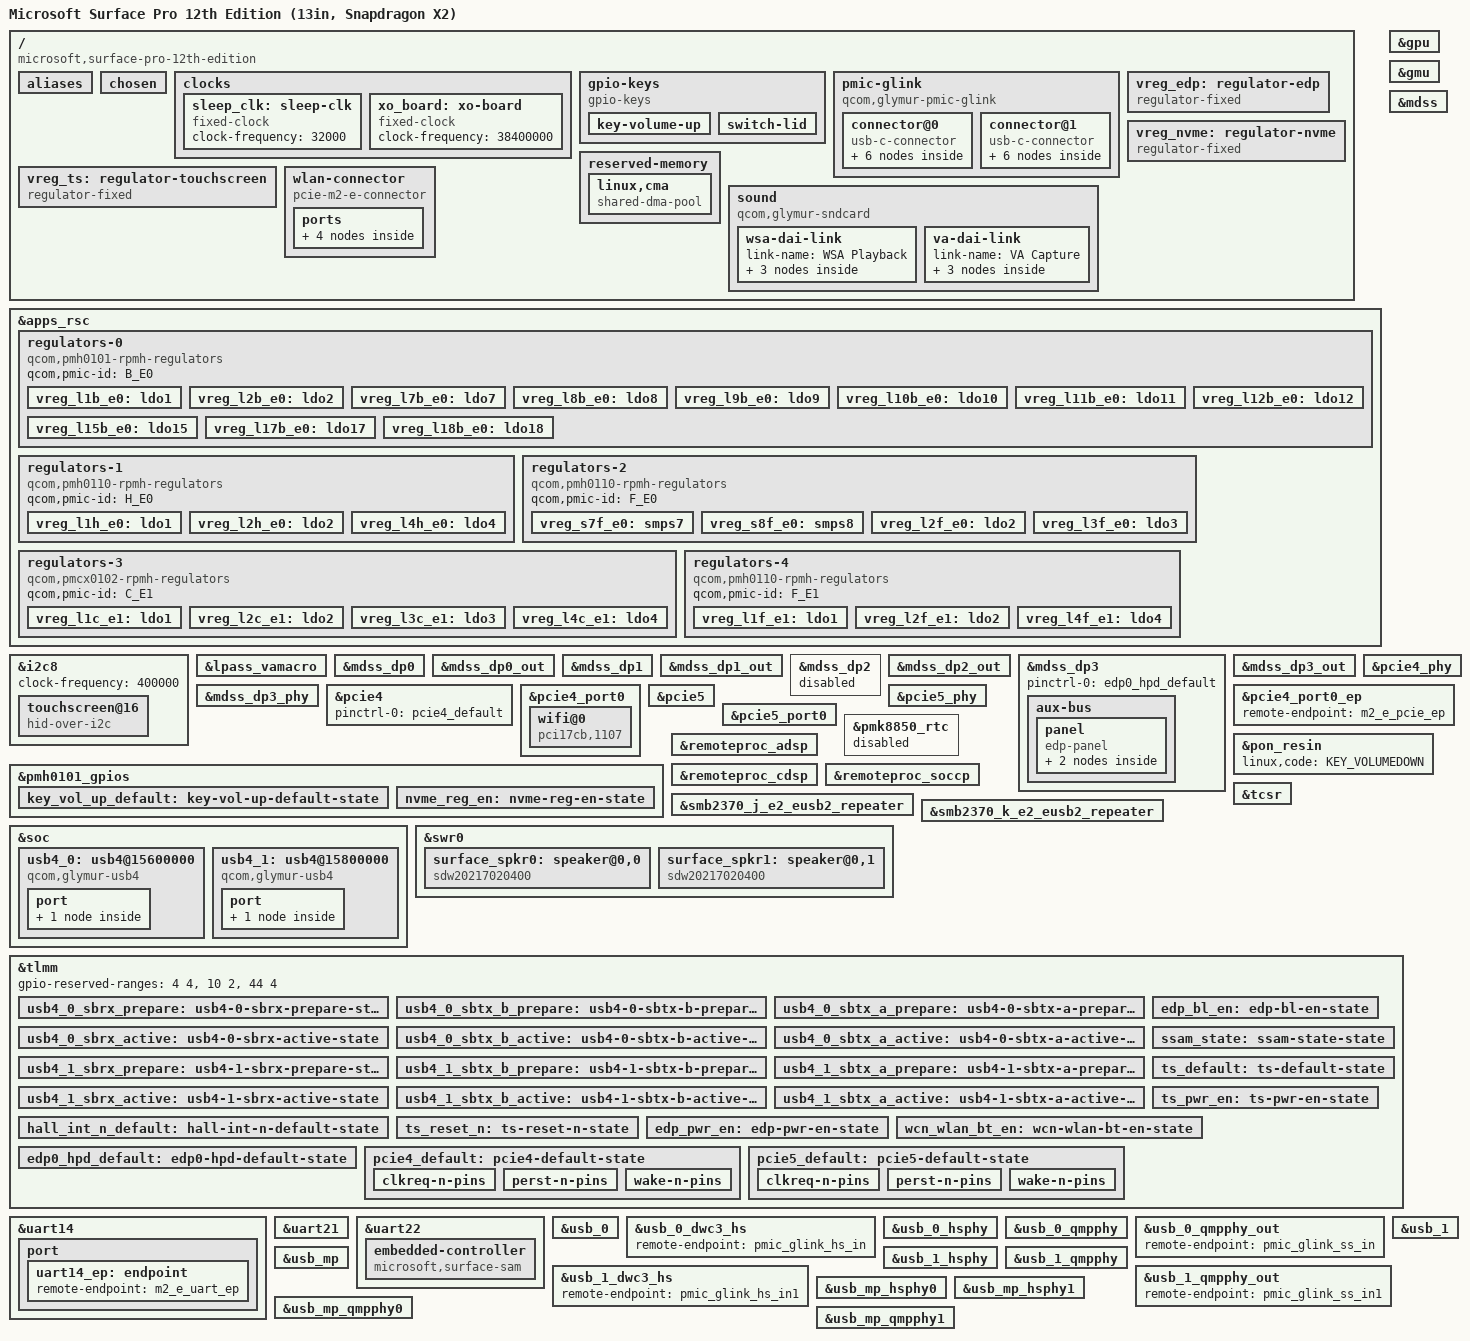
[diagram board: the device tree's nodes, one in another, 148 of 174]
// SPDX-License-Identifier: BSD-3-Clause
/*
 * Microsoft Surface Pro 12th Edition, the 13-inch tablet with the
 * Snapdragon X2 Plus X2P-64-100 or X2 Elite X2E-78-100 (Mahua).
 *
 * Bus and pin assignments follow the ACPI tables in Microsoft's firmware
 * package for the tablet. They match the Surface Laptop 8 13.8-inch apart
 * from the touchscreen, the missing touchpad and the buttons, so the SoC
 * wiring is that laptop's.
 *
 * Copyright (c) Qualcomm Technologies, Inc. and/or its subsidiaries.
 * Copyright (c) 2026, Birk Skyum <birk.skyum@pm.me>
 */
/dts-v1/;

#include "mahua.dtsi"

#include "pmcx0102.dtsi"
#include "pmh0101.dtsi"
#include "pmh0110-glymur.dtsi"
#include "pmk8850.dtsi"
#include "smb2370.dtsi"

#include <dt-bindings/input/gpio-keys.h>
#include <dt-bindings/input/input.h>

/* As mahua-crd.dts: one pmcx0102 die on SPMI0. */
/delete-node/ &pmcx0102_d_e0;
/delete-node/ &pmcx0102_d0_thermal;

/ {
	compatible = "microsoft,surface-pro-12th-edition", "qcom,mahua";
	model = "Microsoft Surface Pro 12th Edition (13in, Snapdragon X2)";

	aliases {
		i2c8 = &i2c8;

		serial0 = &uart21;
		serial1 = &uart14;
	};

	chosen {
	};

	clocks {
		sleep_clk: sleep-clk {
			compatible = "fixed-clock";
			clock-frequency = <32000>;
			#clock-cells = <0>;
		};

		xo_board: xo-board {
			compatible = "fixed-clock";
			clock-frequency = <38400000>;
			#clock-cells = <0>;
		};
	};

	/*
	 * ACPI \_SB.LIGE takes its wake interrupt from GPIO controller pin
	 * 0x440, which is TLMM 2, and \_SB.LID0 reads TLMM 2 directly. On the
	 * tablet the Hall sensor reports the folded keyboard cover.
	 *
	 * MSHW0040 lists two PMIC lines for the volume buttons, up first
	 * (0x72) and down second (0x208), the numbers and order Qualcomm's
	 * reference tables give their volume up and down keys. The Glymur
	 * CRD wires those to PMH0101 GPIO 6 and RESIN.
	 */
	gpio-keys {
		compatible = "gpio-keys";

		pinctrl-0 = <&hall_int_n_default>, <&key_vol_up_default>;
		pinctrl-names = "default";

		key-volume-up {
			label = "Volume Up";
			linux,code = <KEY_VOLUMEUP>;
			gpios = <&pmh0101_gpios 6 GPIO_ACTIVE_LOW>;
			debounce-interval = <15>;
			linux,can-disable;
			wakeup-source;
		};

		switch-lid {
			label = "lid";
			gpios = <&tlmm 2 GPIO_ACTIVE_LOW>;
			linux,input-type = <EV_SW>;
			linux,code = <SW_LID>;
			wakeup-source;
		};
	};

	pmic-glink {
		compatible = "qcom,glymur-pmic-glink",
			     "qcom,pmic-glink";
		#address-cells = <1>;
		#size-cells = <0>;

		connector@0 {
			compatible = "usb-c-connector";
			reg = <0>;
			power-role = "dual";
			data-role = "dual";

			ports {
				#address-cells = <1>;
				#size-cells = <0>;

				port@0 {
					reg = <0>;

					pmic_glink_hs_in: endpoint {
						remote-endpoint = <&usb_0_dwc3_hs>;
					};
				};

				port@1 {
					reg = <1>;
					#address-cells = <1>;
					#size-cells = <0>;

					pmic_glink_ss_in: endpoint@0 {
						reg = <0>;
						remote-endpoint = <&usb_0_qmpphy_out>;
					};

					/* USB4 host router 0 serves this port */
					pmic_glink_usb4_in: endpoint@1 {
						reg = <1>;
						remote-endpoint = <&usb4_0_typec_out>;
					};
				};
			};
		};

		connector@1 {
			compatible = "usb-c-connector";
			reg = <1>;
			power-role = "dual";
			data-role = "dual";

			ports {
				#address-cells = <1>;
				#size-cells = <0>;

				port@0 {
					reg = <0>;

					pmic_glink_hs_in1: endpoint {
						remote-endpoint = <&usb_1_dwc3_hs>;
					};
				};

				port@1 {
					reg = <1>;
					#address-cells = <1>;
					#size-cells = <0>;

					pmic_glink_ss_in1: endpoint@0 {
						reg = <0>;
						remote-endpoint = <&usb_1_qmpphy_out>;
					};

					/* USB4 host router 1 serves this port */
					pmic_glink_usb4_in1: endpoint@1 {
						reg = <1>;
						remote-endpoint = <&usb4_1_typec_out>;
					};
				};
			};
		};
	};

	vreg_edp: regulator-edp {
		compatible = "regulator-fixed";

		regulator-name = "VREG_EDP_3P3";
		regulator-min-microvolt = <3300000>;
		regulator-max-microvolt = <3300000>;

		gpio = <&tlmm 70 GPIO_ACTIVE_HIGH>;
		enable-active-high;

		vin-supply = <&vreg_l8b_e0>;

		pinctrl-0 = <&edp_pwr_en>;
		pinctrl-names = "default";

		regulator-boot-on;
	};

	vreg_nvme: regulator-nvme {
		compatible = "regulator-fixed";

		regulator-name = "VREG_NVME_3P3";
		regulator-min-microvolt = <3300000>;
		regulator-max-microvolt = <3300000>;

		gpio = <&pmh0101_gpios 14 GPIO_ACTIVE_HIGH>;
		enable-active-high;

		pinctrl-0 = <&nvme_reg_en>;
		pinctrl-names = "default";

		regulator-boot-on;
	};

	/*
	 * Touchscreen power switch. The ACPI power table of \_SB.ITCH turns
	 * TLMM 38 on, waits 5 ms, releases the reset on TLMM 48 and waits
	 * 150 ms, and in D3 turns TLMM 38 off and waits 50 ms.
	 */
	vreg_ts: regulator-touchscreen {
		compatible = "regulator-fixed";

		regulator-name = "VREG_TS";

		gpio = <&tlmm 38 GPIO_ACTIVE_HIGH>;
		enable-active-high;
		off-on-delay-us = <50000>;

		pinctrl-0 = <&ts_pwr_en>;
		pinctrl-names = "default";

		regulator-boot-on;
	};

	reserved-memory {
		linux,cma {
			compatible = "shared-dma-pool";
			size = <0x0 0x10000000>;
			reusable;
			linux,cma-default;
		};
	};

	sound {
		compatible = "qcom,glymur-sndcard";
		/*
		 * Two WSA8845 speakers and two DMICs as on the Surface Laptop 8,
		 * whose name selects the DSP topology.
		 */
		model = "GLYMUR-Microsoft-Surface-Laptop-8";
		audio-routing = "SpkrLeft IN", "WSA WSA_SPK1 OUT",
				"SpkrRight IN", "WSA WSA_SPK2 OUT",
				"VA DMIC0", "vdd-micb",
				"VA DMIC1", "vdd-micb";

		wsa-dai-link {
			link-name = "WSA Playback";
			cpu {
				sound-dai = <&q6apmbedai WSA_CODEC_DMA_RX_0>;
			};
			codec {
				sound-dai = <&surface_spkr0>, <&surface_spkr1>,
					    <&swr0 0>, <&lpass_wsamacro 0>;
			};
			platform {
				sound-dai = <&q6apm>;
			};
		};

		va-dai-link {
			link-name = "VA Capture";
			cpu {
				sound-dai = <&q6apmbedai VA_CODEC_DMA_TX_0>;
			};
			codec {
				sound-dai = <&lpass_vamacro 0>;
			};
			platform {
				sound-dai = <&q6apm>;
			};
		};
	};

	wlan-connector {
		compatible = "pcie-m2-e-connector";
		vpcie1v8-supply = <&vreg_l15b_e0>;

		w-disable1-gpios = <&tlmm 117 GPIO_ACTIVE_LOW>;
		w-disable2-gpios = <&tlmm 116 GPIO_ACTIVE_LOW>;

		pinctrl-0 = <&wcn_wlan_bt_en>;
		pinctrl-names = "default";

		ports {
			#address-cells = <1>;
			#size-cells = <0>;

			port@0 {
				reg = <0>;
				#address-cells = <1>;
				#size-cells = <0>;

				m2_e_pcie_ep: endpoint@0 {
					reg = <0>;
					remote-endpoint = <&pcie4_port0_ep>;
				};
			};

			port@3 {
				reg = <3>;
				#address-cells = <1>;
				#size-cells = <0>;

				m2_e_uart_ep: endpoint@0 {
					reg = <0>;
					remote-endpoint = <&uart14_ep>;
				};
			};
		};
	};
};

&apps_rsc {
	/* PMH0101 */
	regulators-0 {
		compatible = "qcom,pmh0101-rpmh-regulators";
		qcom,pmic-id = "B_E0";

		vreg_l1b_e0: ldo1 {
			regulator-name = "vreg_l1b_e0";
			regulator-min-microvolt = <1800000>;
			regulator-max-microvolt = <1800000>;
			regulator-initial-mode = <RPMH_REGULATOR_MODE_HPM>;
		};

		/* Unused */
		vreg_l2b_e0: ldo2 {
			regulator-name = "vreg_l2b_e0";
			regulator-min-microvolt = <1800000>;
			regulator-max-microvolt = <1800000>;
		};

		vreg_l7b_e0: ldo7 {
			regulator-name = "vreg_l7b_e0";
			regulator-min-microvolt = <3072000>;
			regulator-max-microvolt = <3072000>;
			regulator-initial-mode = <RPMH_REGULATOR_MODE_HPM>;
		};

		vreg_l8b_e0: ldo8 {
			regulator-name = "vreg_l8b_e0";
			regulator-min-microvolt = <3072000>;
			regulator-max-microvolt = <3304000>;
			regulator-initial-mode = <RPMH_REGULATOR_MODE_HPM>;
		};

		/* Unused */
		vreg_l9b_e0: ldo9 {
			regulator-name = "vreg_l9b_e0";
			regulator-min-microvolt = <2960000>;
			regulator-max-microvolt = <2960000>;
		};

		vreg_l10b_e0: ldo10 {
			regulator-name = "vreg_l10b_e0";
			regulator-min-microvolt = <1800000>;
			regulator-max-microvolt = <1800000>;
			regulator-initial-mode = <RPMH_REGULATOR_MODE_HPM>;
		};

		vreg_l11b_e0: ldo11 {
			regulator-name = "vreg_l11b_e0";
			regulator-min-microvolt = <1200000>;
			regulator-max-microvolt = <1200000>;
			regulator-initial-mode = <RPMH_REGULATOR_MODE_HPM>;
		};

		/* Unused */
		vreg_l12b_e0: ldo12 {
			regulator-name = "vreg_l12b_e0";
			regulator-min-microvolt = <1200000>;
			regulator-max-microvolt = <1200000>;
		};

		vreg_l15b_e0: ldo15 {
			regulator-name = "vreg_l15b_e0";
			regulator-min-microvolt = <1800000>;
			regulator-max-microvolt = <1800000>;
			regulator-initial-mode = <RPMH_REGULATOR_MODE_HPM>;
			/* Provides reference voltage for many undescribed components */
			regulator-always-on;
		};

		/* Unused */
		vreg_l17b_e0: ldo17 {
			regulator-name = "vreg_l17b_e0";
			regulator-min-microvolt = <2504000>;
			regulator-max-microvolt = <2504000>;
		};

		vreg_l18b_e0: ldo18 {
			regulator-name = "vreg_l18b_e0";
			regulator-min-microvolt = <1200000>;
			regulator-max-microvolt = <1200000>;
			regulator-initial-mode = <RPMH_REGULATOR_MODE_HPM>;

			/* Provides reference voltage for many undescribed components */
			regulator-always-on;
		};
	};

	/* PMH0110 H_E0: USB PHY, PCIe 5 PHY and reference rails (firmware power tables) */
	regulators-1 {
		compatible = "qcom,pmh0110-rpmh-regulators";
		qcom,pmic-id = "H_E0";

		vreg_l1h_e0: ldo1 {
			regulator-name = "vreg_l1h_e0";
			regulator-min-microvolt = <936000>;
			regulator-max-microvolt = <936000>;
			regulator-initial-mode = <RPMH_REGULATOR_MODE_HPM>;
		};

		vreg_l2h_e0: ldo2 {
			regulator-name = "vreg_l2h_e0";
			regulator-min-microvolt = <880000>;
			regulator-max-microvolt = <880000>;
			regulator-initial-mode = <RPMH_REGULATOR_MODE_HPM>;
		};

		vreg_l4h_e0: ldo4 {
			regulator-name = "vreg_l4h_e0";
			regulator-min-microvolt = <1200000>;
			regulator-max-microvolt = <1200000>;
			regulator-initial-mode = <RPMH_REGULATOR_MODE_HPM>;
		};
	};

	/* PMH0110 */
	regulators-2 {
		compatible = "qcom,pmh0110-rpmh-regulators";
		qcom,pmic-id = "F_E0";

		vreg_s7f_e0: smps7 {
			regulator-name = "vreg_s7f_e0";
			regulator-min-microvolt = <1200000>;
			regulator-max-microvolt = <1200000>;
			regulator-initial-mode = <RPMH_REGULATOR_MODE_HPM>;
		};

		vreg_s8f_e0: smps8 {
			regulator-name = "vreg_s8f_e0";
			regulator-min-microvolt = <952000>;
			regulator-max-microvolt = <952000>;
			regulator-initial-mode = <RPMH_REGULATOR_MODE_HPM>;
		};

		vreg_l2f_e0: ldo2 {
			regulator-name = "vreg_l2f_e0";
			regulator-min-microvolt = <936000>;
			regulator-max-microvolt = <936000>;
			regulator-initial-mode = <RPMH_REGULATOR_MODE_HPM>;
		};

		vreg_l3f_e0: ldo3 {
			regulator-name = "vreg_l3f_e0";
			regulator-min-microvolt = <912000>;
			regulator-max-microvolt = <912000>;
			regulator-initial-mode = <RPMH_REGULATOR_MODE_HPM>;
		};
	};

	regulators-3 {
		compatible = "qcom,pmcx0102-rpmh-regulators";
		qcom,pmic-id = "C_E1";

		vreg_l1c_e1: ldo1 {
			regulator-name = "vreg_l1c_e1";
			regulator-min-microvolt = <912000>;
			regulator-max-microvolt = <912000>;
			regulator-initial-mode = <RPMH_REGULATOR_MODE_HPM>;
		};

		vreg_l2c_e1: ldo2 {
			regulator-name = "vreg_l2c_e1";
			regulator-min-microvolt = <1200000>;
			regulator-max-microvolt = <1200000>;
			regulator-initial-mode = <RPMH_REGULATOR_MODE_HPM>;
		};

		vreg_l3c_e1: ldo3 {
			regulator-name = "vreg_l3c_e1";
			regulator-min-microvolt = <936000>;
			regulator-max-microvolt = <936000>;
			regulator-initial-mode = <RPMH_REGULATOR_MODE_HPM>;
		};

		vreg_l4c_e1: ldo4 {
			regulator-name = "vreg_l4c_e1";
			regulator-min-microvolt = <912000>;
			regulator-max-microvolt = <912000>;
			regulator-initial-mode = <RPMH_REGULATOR_MODE_HPM>;
		};
	};

	/* PMH0110 */
	regulators-4 {
		compatible = "qcom,pmh0110-rpmh-regulators";
		qcom,pmic-id = "F_E1";

		vreg_l1f_e1: ldo1 {
			regulator-name = "vreg_l1f_e1";
			regulator-min-microvolt = <904000>;
			regulator-max-microvolt = <904000>;
			regulator-initial-mode = <RPMH_REGULATOR_MODE_HPM>;
		};

		vreg_l2f_e1: ldo2 {
			regulator-name = "vreg_l2f_e1";
			regulator-min-microvolt = <880000>;
			regulator-max-microvolt = <880000>;
			regulator-initial-mode = <RPMH_REGULATOR_MODE_HPM>;
		};

		vreg_l4f_e1: ldo4 {
			regulator-name = "vreg_l4f_e1";
			regulator-min-microvolt = <1200000>;
			regulator-max-microvolt = <1200000>;
			regulator-initial-mode = <RPMH_REGULATOR_MODE_HPM>;
		};
	};
};

&gpu {
	status = "okay";
};

&gmu {
	status = "okay";
};

&i2c8 {
	clock-frequency = <400000>;
	status = "okay";

	/*
	 * ACPI \_SB.ITCH (MSHW0786 and its siblings, by board ID), on I2C9 at
	 * 0x16, with its HID descriptor at register 1. Its interrupt, GPIO
	 * controller pin 0x400, is TLMM 43.
	 */
	touchscreen@16 {
		compatible = "hid-over-i2c";
		reg = <0x16>;
		hid-descr-addr = <0x1>;
		interrupts-extended = <&tlmm 43 IRQ_TYPE_LEVEL_LOW>;
		reset-gpios = <&tlmm 48 GPIO_ACTIVE_LOW>;

		vdd-supply = <&vreg_ts>;
		post-power-on-delay-ms = <5>;
		post-reset-deassert-delay-ms = <150>;

		pinctrl-0 = <&ts_default>, <&ts_reset_n>;
		pinctrl-names = "default";

		wakeup-source;
	};
};

&lpass_vamacro {
	vdd-micb-supply = <&vreg_l1b_e0>;

	pinctrl-0 = <&dmic01_default>;
	pinctrl-names = "default";

	qcom,dmic-sample-rate = <2400000>;
};

&mdss {
	status = "okay";
};

&mdss_dp0 {
	/* DisplayPort alt mode on USB-C port 0, through the pmic-glink bridge */
	status = "okay";

	/* DP IN and USB router link clocks for DisplayPort tunnelled by USB4 router 0 */
	clocks = <&dispcc DISP_CC_MDSS_AHB_CLK>,
		 <&dispcc DISP_CC_MDSS_DPTX0_AUX_CLK>,
		 <&dispcc DISP_CC_MDSS_DPTX0_LINK_CLK>,
		 <&dispcc DISP_CC_MDSS_DPTX0_LINK_INTF_CLK>,
		 <&dispcc DISP_CC_MDSS_DPTX0_PIXEL0_CLK>,
		 <&dispcc DISP_CC_MDSS_DPTX0_PIXEL1_CLK>,
		 <&dispcc DISP_CC_MDSS_DPTX0_LINK_DPIN_CLK>,
		 <&dispcc DISP_CC_MDSS_DPTX0_USB_ROUTER_LINK_INTF_CLK>;
	clock-names = "core_iface",
		      "core_aux",
		      "ctrl_link",
		      "ctrl_link_iface",
		      "stream_pixel",
		      "stream_1_pixel",
		      "ctrl_link_dpin",
		      "ctrl_usb4_link_iface";
};

&mdss_dp0_out {
	link-frequencies = /bits/ 64 <1620000000 2700000000 5400000000 8100000000>;
};

&mdss_dp1 {
	/* DisplayPort alt mode on USB-C port 1, through the pmic-glink bridge */
	status = "okay";

	/* DP IN and USB router link clocks for DisplayPort tunnelled by USB4 router 1 */
	clocks = <&dispcc DISP_CC_MDSS_AHB_CLK>,
		 <&dispcc DISP_CC_MDSS_DPTX1_AUX_CLK>,
		 <&dispcc DISP_CC_MDSS_DPTX1_LINK_CLK>,
		 <&dispcc DISP_CC_MDSS_DPTX1_LINK_INTF_CLK>,
		 <&dispcc DISP_CC_MDSS_DPTX1_PIXEL0_CLK>,
		 <&dispcc DISP_CC_MDSS_DPTX1_PIXEL1_CLK>,
		 <&dispcc DISP_CC_MDSS_DPTX1_LINK_DPIN_CLK>,
		 <&dispcc DISP_CC_MDSS_DPTX1_USB_ROUTER_LINK_INTF_CLK>;
	clock-names = "core_iface",
		      "core_aux",
		      "ctrl_link",
		      "ctrl_link_iface",
		      "stream_pixel",
		      "stream_1_pixel",
		      "ctrl_link_dpin",
		      "ctrl_usb4_link_iface";
};

&mdss_dp1_out {
	link-frequencies = /bits/ 64 <1620000000 2700000000 5400000000 8100000000>;
};

&mdss_dp2 {
	/* No USB-C port uses the third combo PHY, which DP2 drives. */
	status = "disabled";
};

&mdss_dp2_out {
	link-frequencies = /bits/ 64 <1620000000 2700000000 5400000000 8100000000>;
};

&mdss_dp3 {
	/delete-property/ #sound-dai-cells;

	pinctrl-0 = <&edp0_hpd_default>;
	pinctrl-names = "default";

	status = "okay";

	aux-bus {
		panel {
			/*
			 * The enable (TLMM 18), power (TLMM 70) and hot-plug
			 * (TLMM 119) pins are the ones the firmware's power
			 * tables switch for the display, on every board ID. No
			 * backlight node: the OLED panel takes its brightness
			 * over the AUX channel.
			 */
			compatible = "edp-panel";
			enable-gpios = <&tlmm 18 GPIO_ACTIVE_HIGH>;
			power-supply = <&vreg_edp>;

			pinctrl-0 = <&edp_bl_en>;
			pinctrl-names = "default";

			port {
				edp_panel_in: endpoint {
					remote-endpoint = <&mdss_dp3_out>;
				};
			};
		};
	};
};

&mdss_dp3_out {
	/*
	 * 8.1 Gbps (HBR3) has not been validated on this board's eDP link;
	 * 5.4 Gbps is the highest rate it has run at.
	 */
	data-lanes = <0 1 2 3>;
	link-frequencies = /bits/ 64 <1620000000 2700000000 5400000000>;

	remote-endpoint = <&edp_panel_in>;
};

&mdss_dp3_phy {
	vdda-phy-supply = <&vreg_l2f_e1>;
	vdda-pll-supply = <&vreg_l4f_e1>;

	status = "okay";
};

&pcie4 {
	pinctrl-0 = <&pcie4_default>;
	pinctrl-names = "default";

	status = "okay";
};

&pcie4_phy {
	vdda-phy-supply = <&vreg_l1c_e1>;
	vdda-pll-supply = <&vreg_l4f_e1>;

	status = "okay";
};

&pcie4_port0 {
	reset-gpios = <&tlmm 146 GPIO_ACTIVE_LOW>;
	wake-gpios = <&tlmm 148 GPIO_ACTIVE_LOW>;

	/*
	 * The WCN7850 module has no usable MAC address of its own; the board's
	 * address lives in the Qualcomm DPP partition on the firmware SPI-NOR.
	 * The boot loader stores it here as "local-mac-address".
	 */
	wifi@0 {
		compatible = "pci17cb,1107";
		reg = <0x10000 0x0 0x0 0x0 0x0>;

		/* The WCN7850's hardware rfkill input reads as "radio off". */
		disable-rfkill;
	};
};

&pcie4_port0_ep {
	remote-endpoint = <&m2_e_pcie_ep>;
};

&pcie5 {
	vddpe-3v3-supply = <&vreg_nvme>;

	pinctrl-0 = <&pcie5_default>;
	pinctrl-names = "default";

	status = "okay";
};

&pcie5_phy {
	vdda-phy-supply = <&vreg_l2f_e0>;
	vdda-pll-supply = <&vreg_l4h_e0>;

	status = "okay";
};

&pcie5_port0 {
	/* ACPI PCI5.RP1 wakes from GPIO controller pin 0x1c0, TLMM 154. */
	reset-gpios = <&tlmm 152 GPIO_ACTIVE_LOW>;
	wake-gpios = <&tlmm 154 GPIO_ACTIVE_LOW>;
};

&pmh0101_gpios {
	key_vol_up_default: key-vol-up-default-state {
		pins = "gpio6";
		function = "normal";
		output-disable;
		bias-pull-up;
	};

	nvme_reg_en: nvme-reg-en-state {
		pins = "gpio14";
		function = "normal";
		bias-disable;
	};
};

&pmk8850_rtc {
	/*
	 * The firmware keeps no UEFI offset for this counter; the time is
	 * kept by SAM (rtc-surface).
	 */
	status = "disabled";
};

&pon_resin {
	linux,code = <KEY_VOLUMEDOWN>;

	status = "okay";
};

&remoteproc_adsp {
	firmware-name = "qcom/glymur/microsoft/mahua/qcadsp8480.mbn",
			"qcom/glymur/microsoft/mahua/adsp_dtbs.elf";

	status = "okay";
};

&remoteproc_cdsp {
	firmware-name = "qcom/glymur/microsoft/mahua/qccdsp8480.mbn",
			"qcom/glymur/microsoft/mahua/cdsp_dtbs.elf";

	status = "okay";
};

&remoteproc_soccp {
	firmware-name = "qcom/glymur/microsoft/surface-pro-12th-edition/soccp.mbn",
			"qcom/glymur/microsoft/surface-pro-12th-edition/soccp_dtb.mbn";
};

&smb2370_j_e2_eusb2_repeater {
	vdd18-supply = <&vreg_l15b_e0>;
	vdd3-supply = <&vreg_l7b_e0>;
};

&smb2370_k_e2_eusb2_repeater {
	vdd18-supply = <&vreg_l15b_e0>;
	vdd3-supply = <&vreg_l7b_e0>;
};

&soc {
	/* USB4 host router 0, for USB-C port 0 */
	usb4_0: usb4@15600000 {
		compatible = "qcom,glymur-usb4";
		reg = <0x0 0x15600000 0x0 0x100000>;

		interrupts = <GIC_SPI 70 IRQ_TYPE_LEVEL_HIGH>,
			     <GIC_SPI 121 IRQ_TYPE_LEVEL_HIGH>;
		interrupt-names = "nhi", "mcu";

		clocks = <&gcc GCC_CFG_NOC_USB_ANOC_AHB_CLK>,
			 <&gcc GCC_CFG_NOC_USB_ANOC_SOUTH_AHB_CLK>,
			 <&gcc GCC_AGGRE_USB4_0_AXI_CLK>,
			 <&gcc GCC_USB4_0_CFG_AHB_CLK>,
			 <&gcc GCC_USB4_0_MASTER_CLK>,
			 <&gcc GCC_USB4_0_SB_IF_CLK>,
			 <&gcc GCC_USB4_0_TMU_CLK>,
			 <&gcc GCC_USB4_0_SYS_CLK>,
			 <&gcc GCC_USB4_0_UC_HRR_CLK>,
			 <&gcc GCC_USB4_0_DP0_CLK>,
			 <&gcc GCC_USB4_0_DP1_CLK>,
			 <&gcc GCC_USB4_0_PHY_PCIE_PIPE_CLK>,
			 <&gcc GCC_USB4_0_PHY_USB_PIPE_CLK>;
		clock-names = "anoc_ahb",
			      "anoc_south_ahb",
			      "aggre_axi",
			      "cfg_ahb",
			      "master",
			      "sb_if",
			      "tmu",
			      "sys",
			      "uc_hrr",
			      "dp0",
			      "dp1",
			      "pcie_pipe",
			      "usb_pipe";
		assigned-clocks = <&gcc GCC_USB4_0_MASTER_CLK_SRC>,
				  <&gcc GCC_USB4_0_TMU_CLK_SRC>;
		assigned-clock-rates = <355333500>, <250000000>;

		resets = <&gcc GCC_USB4_0_BCR>,
			 <&gcc GCC_USB4PHY_0_PHY_PRIM_BCR>,
			 <&gcc GCC_USB4_0_DP0_PHY_PRIM_BCR>;
		reset-names = "router", "phy", "dp";

		power-domains = <&gcc GCC_USB4_0_GDSC>;
		required-opps = <&rpmhpd_opp_nom>;

		interconnects = <&aggre4_noc MASTER_USB4_0 QCOM_ICC_TAG_ALWAYS
				 &mc_virt SLAVE_EBI1 QCOM_ICC_TAG_ALWAYS>,
				<&hsc_noc MASTER_APPSS_PROC QCOM_ICC_TAG_ACTIVE_ONLY
				 &config_noc SLAVE_USB4_0 QCOM_ICC_TAG_ACTIVE_ONLY>;
		interconnect-names = "usb4-ddr", "apps-usb4";

		iommus = <&apps_smmu 0x1440 0x0>;

		phys = <&usb_0_qmpphy QMP_USB43DP_USB4_PHY>;
		phy-names = "usb4";

		pinctrl-names = "rx-prepare", "txb-prepare", "txa-prepare",
				"rx-active", "txb-active", "txa-active";
		pinctrl-0 = <&usb4_0_sbrx_prepare>;
		pinctrl-1 = <&usb4_0_sbtx_b_prepare>;
		pinctrl-2 = <&usb4_0_sbtx_a_prepare>;
		pinctrl-3 = <&usb4_0_sbrx_active>;
		pinctrl-4 = <&usb4_0_sbtx_b_active>;
		pinctrl-5 = <&usb4_0_sbtx_a_active>;

		qcom,tcsr = <&tcsr>;
		qcom,router-index = <0>;
		firmware-name = "qcom/glymur/surface-pro-12th-edition/usb4-router-legacy.bin";

		mode-switch;
		orientation-switch;

		port {
			usb4_0_typec_out: endpoint {
				remote-endpoint = <&pmic_glink_usb4_in>;
			};
		};
	};

	/*
	 * USB4 host router 1, for USB-C port 1. It has
	 * the v2 MCU layout and its own firmware image. Its registers from
	 * 0xe030 on also need the power domain of the PCIe controller it
	 * tunnels. The "nhi" interrupt and the IOMMU stream are taken from the
	 * ACPI tables by position and elimination.
	 */
	usb4_1: usb4@15800000 {
		compatible = "qcom,glymur-usb4";
		reg = <0x0 0x15800000 0x0 0x100000>;

		interrupts = <GIC_SPI 736 IRQ_TYPE_LEVEL_HIGH>,
			     <GIC_SPI 941 IRQ_TYPE_LEVEL_HIGH>;
		interrupt-names = "nhi", "mcu";

		clocks = <&gcc GCC_CFG_NOC_USB_ANOC_AHB_CLK>,
			 <&gcc GCC_CFG_NOC_USB_ANOC_SOUTH_AHB_CLK>,
			 <&gcc GCC_AGGRE_USB4_1_AXI_CLK>,
			 <&gcc GCC_USB4_1_CFG_AHB_CLK>,
			 <&gcc GCC_USB4_1_MASTER_CLK>,
			 <&gcc GCC_USB4_1_SB_IF_CLK>,
			 <&gcc GCC_USB4_1_TMU_CLK>,
			 <&gcc GCC_USB4_1_SYS_CLK>,
			 <&gcc GCC_USB4_1_UC_HRR_CLK>,
			 <&gcc GCC_USB4_1_DP0_CLK>,
			 <&gcc GCC_USB4_1_DP1_CLK>,
			 <&gcc GCC_USB4_1_PHY_PCIE_PIPE_CLK>,
			 <&gcc GCC_USB4_1_PHY_USB_PIPE_CLK>;
		clock-names = "anoc_ahb",
			      "anoc_south_ahb",
			      "aggre_axi",
			      "cfg_ahb",
			      "master",
			      "sb_if",
			      "tmu",
			      "sys",
			      "uc_hrr",
			      "dp0",
			      "dp1",
			      "pcie_pipe",
			      "usb_pipe";
		assigned-clocks = <&gcc GCC_USB4_1_MASTER_CLK_SRC>,
				  <&gcc GCC_USB4_1_TMU_CLK_SRC>;
		assigned-clock-rates = <355333500>, <250000000>;

		resets = <&gcc GCC_USB4_1_BCR>,
			 <&gcc GCC_USB4PHY_1_PHY_SEC_BCR>,
			 <&gcc GCC_USB4_1_DP0_PHY_SEC_BCR>;
		reset-names = "router", "phy", "dp";

		power-domains = <&gcc GCC_USB4_1_GDSC>,
				<&gcc GCC_PCIE_1_TUNNEL_GDSC>;
		power-domain-names = "usb4", "pcie-tunnel";
		required-opps = <&rpmhpd_opp_nom>;

		interconnects = <&aggre4_noc MASTER_USB4_1 QCOM_ICC_TAG_ALWAYS
				 &mc_virt SLAVE_EBI1 QCOM_ICC_TAG_ALWAYS>,
				<&hsc_noc MASTER_APPSS_PROC QCOM_ICC_TAG_ACTIVE_ONLY
				 &config_noc SLAVE_USB4_1 QCOM_ICC_TAG_ACTIVE_ONLY>;
		interconnect-names = "usb4-ddr", "apps-usb4";

		iommus = <&apps_smmu 0x1600 0x0>;

		phys = <&usb_1_qmpphy QMP_USB43DP_USB4_PHY>;
		phy-names = "usb4";

		pinctrl-names = "rx-prepare", "txb-prepare", "txa-prepare",
				"rx-active", "txb-active", "txa-active";
		pinctrl-0 = <&usb4_1_sbrx_prepare>;
		pinctrl-1 = <&usb4_1_sbtx_b_prepare>;
		pinctrl-2 = <&usb4_1_sbtx_a_prepare>;
		pinctrl-3 = <&usb4_1_sbrx_active>;
		pinctrl-4 = <&usb4_1_sbtx_b_active>;
		pinctrl-5 = <&usb4_1_sbtx_a_active>;

		qcom,tcsr = <&tcsr>;
		qcom,router-index = <1>;
		firmware-name = "qcom/glymur/surface-pro-12th-edition/usb4-router-v2.bin";

		mode-switch;
		orientation-switch;

		port {
			usb4_1_typec_out: endpoint {
				remote-endpoint = <&pmic_glink_usb4_in1>;
			};
		};
	};
};

&swr0 {
	status = "okay";

	surface_spkr0: speaker@0,0 {
		compatible = "sdw20217020400";
		reg = <0 0>;
		reset-gpios = <&tlmm 204 GPIO_ACTIVE_LOW>;
		#sound-dai-cells = <0>;
		sound-name-prefix = "SpkrLeft";
		vdd-1p8-supply = <&vreg_l15b_e0>;
		vdd-io-supply = <&vreg_l18b_e0>;
		qcom,port-mapping = <1 2 3 7 12 14>;
	};

	surface_spkr1: speaker@0,1 {
		compatible = "sdw20217020400";
		reg = <0 1>;
		reset-gpios = <&tlmm 204 GPIO_ACTIVE_LOW>;
		#sound-dai-cells = <0>;
		sound-name-prefix = "SpkrRight";
		vdd-1p8-supply = <&vreg_l15b_e0>;
		vdd-io-supply = <&vreg_l18b_e0>;
		qcom,port-mapping = <4 5 6 7 13 15>;
	};
};

&tcsr {
	vdda-qrefrpt0-0p9-supply = <&vreg_l2f_e1>;
	vdda-qrefrpt1-0p9-supply = <&vreg_l2f_e1>;
	vdda-qrefrpt2-0p9-supply = <&vreg_l2f_e1>;
	vdda-qrefrpt3-0p9-supply = <&vreg_l1f_e1>;
	vdda-qrefrpt4-0p9-supply = <&vreg_l2h_e0>;
	vdda-qrefrpt5-0p9-supply = <&vreg_l2h_e0>;
	vdda-qrefrx0-0p9-supply = <&vreg_l2f_e1>;
	vdda-qrefrx1-0p9-supply = <&vreg_l2f_e1>;
	vdda-qrefrx2-0p9-supply = <&vreg_l2f_e1>;
	vdda-qrefrx3-0p9-supply = <&vreg_l2h_e0>;
	vdda-qreftx1-0p9-supply = <&vreg_l1f_e1>;
	vdda-refgen3-0p9-supply = <&vreg_l1f_e1>;
	vdda-refgen3-1p2-supply = <&vreg_l4f_e1>;
};

&tlmm {
	gpio-reserved-ranges = <4 4>, /* EC Secure I3C */
			       <10 2>, /* OOB UART */
			       <44 4>; /* TPM */

	/*
	 * USB4 router 0 sideband pads, in the order the router start-up sets
	 * them: prepare states before the router reset, active states after it.
	 */
	usb4_0_sbrx_prepare: usb4-0-sbrx-prepare-state {
		pins = "gpio163";
		function = "gpio";
		bias-pull-down;
		output-disable;
	};

	usb4_0_sbtx_b_prepare: usb4-0-sbtx-b-prepare-state {
		pins = "gpio165";
		drive-strength = <10>;
		output-high;
	};

	usb4_0_sbtx_a_prepare: usb4-0-sbtx-a-prepare-state {
		pins = "gpio164";
		function = "gpio";
		drive-strength = <10>;
		bias-pull-down;
		output-low;
	};

	usb4_0_sbrx_active: usb4-0-sbrx-active-state {
		pins = "gpio163";
		function = "usb0_sbrx";
		bias-disable;
		output-disable;
	};

	usb4_0_sbtx_b_active: usb4-0-sbtx-b-active-state {
		pins = "gpio165";
		function = "usb0_sbtx";
		drive-strength = <10>;
	};

	usb4_0_sbtx_a_active: usb4-0-sbtx-a-active-state {
		pins = "gpio164";
		function = "usb0_sbtx";
		drive-strength = <10>;
		bias-pull-up;
		output-disable;
	};

	/* USB4 router 1 sideband pads, as for router 0 */
	usb4_1_sbrx_prepare: usb4-1-sbrx-prepare-state {
		pins = "gpio172";
		function = "gpio";
		bias-pull-down;
		output-disable;
	};

	usb4_1_sbtx_b_prepare: usb4-1-sbtx-b-prepare-state {
		pins = "gpio174";
		drive-strength = <10>;
		output-high;
	};

	usb4_1_sbtx_a_prepare: usb4-1-sbtx-a-prepare-state {
		pins = "gpio173";
		function = "gpio";
		drive-strength = <10>;
		bias-pull-down;
		output-low;
	};

	usb4_1_sbrx_active: usb4-1-sbrx-active-state {
		pins = "gpio172";
		function = "usb1_sbrx";
		bias-disable;
		output-disable;
	};

	usb4_1_sbtx_b_active: usb4-1-sbtx-b-active-state {
		pins = "gpio174";
		function = "usb1_sbtx";
		drive-strength = <10>;
	};

	usb4_1_sbtx_a_active: usb4-1-sbtx-a-active-state {
		pins = "gpio173";
		function = "usb1_sbtx";
		drive-strength = <10>;
		bias-pull-up;
		output-disable;
	};

	hall_int_n_default: hall-int-n-default-state {
		pins = "gpio2";
		function = "gpio";
		bias-disable;
	};

	edp_bl_en: edp-bl-en-state {
		pins = "gpio18";
		function = "gpio";
		drive-strength = <16>;
		bias-disable;
	};

	ssam_state: ssam-state-state {
		pins = "gpio71";
		function = "gpio";
		bias-disable;
	};

	ts_default: ts-default-state {
		pins = "gpio43";
		function = "gpio";
		drive-strength = <2>;
		bias-disable;
	};

	ts_pwr_en: ts-pwr-en-state {
		pins = "gpio38";
		function = "gpio";
		drive-strength = <4>;
		bias-disable;
	};

	ts_reset_n: ts-reset-n-state {
		pins = "gpio48";
		function = "gpio";
		drive-strength = <16>;
		bias-disable;
	};

	edp_pwr_en: edp-pwr-en-state {
		pins = "gpio70";
		function = "gpio";
		drive-strength = <16>;
		bias-disable;
	};

	wcn_wlan_bt_en: wcn-wlan-bt-en-state {
		pins = "gpio116", "gpio117";
		function = "gpio";
		drive-strength = <2>;
		bias-disable;
	};

	edp0_hpd_default: edp0-hpd-default-state {
		pins = "gpio119";
		function = "edp0_hot";
		bias-disable;
	};

	pcie4_default: pcie4-default-state {
		clkreq-n-pins {
			pins = "gpio147";
			function = "pcie4_clk_req_n";
			drive-strength = <2>;
			bias-pull-up;
		};

		perst-n-pins {
			pins = "gpio146";
			function = "gpio";
			drive-strength = <2>;
			bias-disable;
		};

		wake-n-pins {
			pins = "gpio148";
			function = "gpio";
			drive-strength = <2>;
			bias-pull-up;
		};
	};

	pcie5_default: pcie5-default-state {
		clkreq-n-pins {
			pins = "gpio153";
			function = "pcie5_clk_req_n";
			drive-strength = <2>;
			bias-pull-up;
		};

		perst-n-pins {
			pins = "gpio152";
			function = "gpio";
			drive-strength = <2>;
			bias-disable;
		};

		wake-n-pins {
			pins = "gpio154";
			function = "gpio";
			drive-strength = <2>;
			bias-pull-up;
		};
	};
};

&uart14 {
	status = "okay";

	port {
		uart14_ep: endpoint {
			remote-endpoint = <&m2_e_uart_ep>;
		};
	};
};

&uart21 {
	status = "okay";
};

/*
 * ACPI UR23 @ 0x898000: Surface Serial Hub, MSHW0084. Its interrupt, GPIO
 * controller pin 0x300, is TLMM 71, the pin it also reads directly.
 */
&uart22 {
	status = "okay";

	embedded-controller {
		compatible = "microsoft,surface-sam";

		interrupts-extended = <&tlmm 71 IRQ_TYPE_EDGE_RISING>;

		current-speed = <4000000>;

		pinctrl-0 = <&ssam_state>;
		pinctrl-names = "default";
	};
};

&usb_0 {
	/* Dual role: UCSI over the SOCCP drives the role switch. */
	dr_mode = "otg";
	/* U2/U3 exit across a USB4 tunnel needs GUSB3PIPECTL.DEPOCHANGE clear. */
	snps,dis-del-phy-power-chg-quirk;
	/* The SuperSpeed port can be tunnelled through USB4 router 0 */
	usb4-host-interface = <&usb4_0>;

	status = "okay";
};

&usb_0_dwc3_hs {
	remote-endpoint = <&pmic_glink_hs_in>;
};

&usb_0_hsphy {
	vdd-supply = <&vreg_l3f_e0>;
	vdda12-supply = <&vreg_l4h_e0>;

	phys = <&smb2370_j_e2_eusb2_repeater>;

	status = "okay";
};

&usb_0_qmpphy {
	/* Shared USB4 DP producer/AUX block written during USB4 PHY setup. */
	reg = <0x0 0x00fd5000 0x0 0x8000>,
	      <0x0 0x00fe6000 0x0 0xcc>;
	reg-names = "phy", "usb4-dp-aux";
	qcom,usb4-rx-eq = <0x6f>;
	vdda-phy-supply = <&vreg_l3f_e0>;
	vdda-pll-supply = <&vreg_l4h_e0>;
	refgen-supply = <&vreg_l2f_e0>;

	/* USB4 mode also needs the P2RR2P pipe clock. */
	clocks = <&gcc GCC_USB3_PRIM_PHY_AUX_CLK>,
		 <&rpmhcc RPMH_CXO_CLK>,
		 <&gcc GCC_USB3_PRIM_PHY_COM_AUX_CLK>,
		 <&gcc GCC_USB3_PRIM_PHY_PIPE_CLK>,
		 <&gcc GCC_USB4_0_PHY_P2RR2P_PIPE_CLK>;
	clock-names = "aux",
		      "ref",
		      "com_aux",
		      "usb3_pipe",
		      "p2rr2p_pipe";

	status = "okay";
};

&usb_0_qmpphy_out {
	remote-endpoint = <&pmic_glink_ss_in>;
};

&usb_1 {
	dr_mode = "otg";
	snps,dis-del-phy-power-chg-quirk;
	/* The SuperSpeed port can be tunnelled through USB4 router 1 */
	usb4-host-interface = <&usb4_1>;

	status = "okay";
};

&usb_1_dwc3_hs {
	remote-endpoint = <&pmic_glink_hs_in1>;
};

&usb_1_hsphy {
	vdd-supply = <&vreg_l3f_e0>;
	vdda12-supply = <&vreg_l4h_e0>;

	phys = <&smb2370_k_e2_eusb2_repeater>;

	status = "okay";
};

&usb_1_qmpphy {
	/*
	 * USB4 DP producer/AUX blocks written during USB4 PHY setup: the one
	 * usb_0_qmpphy describes too, and a second one the platform's Windows
	 * driver writes first for this router.
	 */
	reg = <0x0 0x00fde000 0x0 0x8000>,
	      <0x0 0x00fe6000 0x0 0xcc>,
	      <0x0 0x088f0000 0x0 0xcc>;
	reg-names = "phy", "usb4-dp-aux", "usb4-dp-aux2";
	qcom,usb4-rx-eq = <0x6f>;
	vdda-phy-supply = <&vreg_l1h_e0>;
	vdda-pll-supply = <&vreg_l4h_e0>;
	refgen-supply = <&vreg_l2f_e0>;

	/* USB4 mode also needs the P2RR2P pipe clock. */
	clocks = <&gcc GCC_USB3_SEC_PHY_AUX_CLK>,
		 <&tcsr TCSR_USB4_1_CLKREF_EN>,
		 <&gcc GCC_USB3_SEC_PHY_COM_AUX_CLK>,
		 <&gcc GCC_USB3_SEC_PHY_PIPE_CLK>,
		 <&gcc GCC_USB4_1_PHY_P2RR2P_PIPE_CLK>;
	clock-names = "aux",
		      "ref",
		      "com_aux",
		      "usb3_pipe",
		      "p2rr2p_pipe";

	status = "okay";
};

&usb_1_qmpphy_out {
	remote-endpoint = <&pmic_glink_ss_in1>;
};

/*
 * Multiport controller (ACPI USB3), host only. Its second port is the one
 * the ACPI tables mark connectable. ACPI I2C6 carries its two PTN3222 eUSB2
 * repeaters (0x43 and 0x4f), whose enable pins, TLMM 8 and 184, the
 * firmware drives high when it powers the controller. As on the Surface
 * Laptop 8, they are left as the firmware configured them.
 */
&usb_mp {
	status = "okay";
};

&usb_mp_hsphy0 {
	vdd-supply = <&vreg_l2h_e0>;
	vdda12-supply = <&vreg_l4h_e0>;

	status = "okay";
};

&usb_mp_hsphy1 {
	vdd-supply = <&vreg_l2h_e0>;
	vdda12-supply = <&vreg_l4h_e0>;

	status = "okay";
};

&usb_mp_qmpphy0 {
	vdda-phy-supply = <&vreg_l2h_e0>;
	vdda-pll-supply = <&vreg_l4h_e0>;
	refgen-supply = <&vreg_l4f_e1>;

	status = "okay";
};

&usb_mp_qmpphy1 {
	vdda-phy-supply = <&vreg_l2h_e0>;
	vdda-pll-supply = <&vreg_l4h_e0>;
	refgen-supply = <&vreg_l4f_e1>;

	status = "okay";
};
